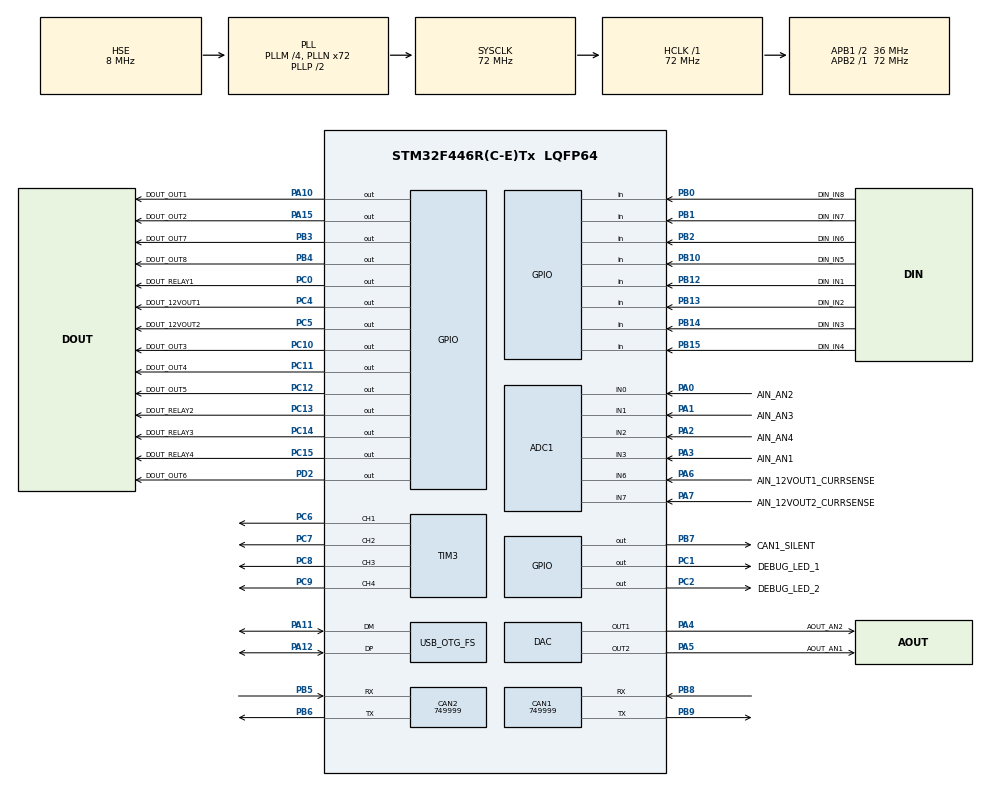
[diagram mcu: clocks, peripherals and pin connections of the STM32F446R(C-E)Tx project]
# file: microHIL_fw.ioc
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ADC1.Channel-0\#ChannelRegularConversion=ADC_CHANNEL_0
ADC1.NbrOfConversionFlag=1
ADC1.Rank-0\#ChannelRegularConversion=1
ADC1.SamplingTime-0\#ChannelRegularConversion=ADC_SAMPLETIME_3CYCLES
ADC1.master=1
CAN1.BS1=CAN_BS1_1TQ
CAN1.BS2=CAN_BS2_1TQ
CAN1.CalculateBaudRate=749999
CAN1.CalculateTimeBit=1333
CAN1.CalculateTimeQuantum=444.44444444444446
CAN2.BS1=CAN_BS1_1TQ
CAN2.BS2=CAN_BS2_1TQ
CAN2.CalculateBaudRate=749999
CAN2.CalculateTimeBit=1333
CAN2.CalculateTimeQuantum=444.44444444444446
Mcu.Family=STM32F4
Mcu.Name=STM32F446R(C-E)Tx
Mcu.Package=LQFP64
NVIC.OTG_FS_IRQn=true\:0\:0\:false\:false\:true\:false\:true\:true
NVIC.PriorityGroup=NVIC_PRIORITYGROUP_4
PA0-WKUP.GPIO_Label=AIN_AN2
PA0-WKUP.Signal=ADCx_IN0
PA1.GPIO_Label=AIN_AN3
PA1.Signal=ADCx_IN1
PA10.GPIO_Label=DOUT_OUT1
PA10.Signal=GPIO_Output
PA11.Mode=Device_Only
PA11.Signal=USB_OTG_FS_DM
PA12.Mode=Device_Only
PA12.Signal=USB_OTG_FS_DP
PA13.Mode=Serial_Wire
PA13.Signal=SYS_JTMS-SWDIO
PA14.Mode=Serial_Wire
PA14.Signal=SYS_JTCK-SWCLK
PA15.GPIO_Label=DOUT_OUT2
PA15.Signal=GPIO_Output
PA2.GPIO_Label=AIN_AN4
PA2.Signal=ADCx_IN2
PA3.GPIO_Label=AIN_AN1
PA3.Signal=ADCx_IN3
PA4.GPIO_Label=AOUT_AN2
PA4.Signal=COMP_DAC1_group
PA5.GPIO_Label=AOUT_AN1
PA5.Signal=COMP_DAC2_group
PA6.GPIO_Label=AIN_12VOUT1_CURRSENSE
PA6.Signal=ADCx_IN6
PA7.GPIO_Label=AIN_12VOUT2_CURRSENSE
PA7.Signal=ADCx_IN7
PB0.GPIO_Label=DIN_IN8
PB0.Signal=GPIO_Input
PB1.GPIO_Label=DIN_IN7
PB1.Signal=GPIO_Input
PB10.GPIO_Label=DIN_IN5
PB10.Signal=GPIO_Input
PB12.GPIO_Label=DIN_IN1
PB12.Signal=GPIO_Input
PB13.GPIO_Label=DIN_IN2
PB13.Signal=GPIO_Input
PB14.GPIO_Label=DIN_IN3
PB14.Signal=GPIO_Input
PB15.GPIO_Label=DIN_IN4
PB15.Signal=GPIO_Input
PB2.GPIO_Label=DIN_IN6
PB2.Signal=GPIO_Input
PB3.GPIO_Label=DOUT_OUT7
PB3.Signal=GPIO_Output
PB4.GPIO_Label=DOUT_OUT8
PB4.Signal=GPIO_Output
PB5.Mode=CAN_Activate
PB5.Signal=CAN2_RX
PB6.Mode=CAN_Activate
PB6.Signal=CAN2_TX
PB7.GPIO_Label=CAN1_SILENT
PB7.Signal=GPIO_Output
PB8.Mode=CAN_Activate
PB8.Signal=CAN1_RX
PB9.Mode=CAN_Activate
PB9.Signal=CAN1_TX
PC0.GPIO_Label=DOUT_RELAY1
PC0.Signal=GPIO_Output
PC1.GPIO_Label=DEBUG_LED_1
PC1.Signal=GPIO_Output
PC10.GPIO_Label=DOUT_OUT3
PC10.Signal=GPIO_Output
PC11.GPIO_Label=DOUT_OUT4
PC11.Signal=GPIO_Output
PC12.GPIO_Label=DOUT_OUT5
PC12.Signal=GPIO_Output
PC13.GPIO_Label=DOUT_RELAY2
PC13.Signal=GPIO_Output
PC14-OSC32_IN.GPIO_Label=DOUT_RELAY3
PC14-OSC32_IN.Signal=GPIO_Output
PC15-OSC32_OUT.GPIO_Label=DOUT_RELAY4
PC15-OSC32_OUT.Signal=GPIO_Output
PC2.GPIO_Label=DEBUG_LED_2
PC2.Signal=GPIO_Output
PC4.GPIO_Label=DOUT_12VOUT1
PC4.Signal=GPIO_Output
PC5.GPIO_Label=DOUT_12VOUT2
PC5.Signal=GPIO_Output
PC6.Signal=S_TIM3_CH1
PC7.Signal=S_TIM3_CH2
PC8.Signal=S_TIM3_CH3
PC9.Signal=S_TIM3_CH4
PD2.GPIO_Label=DOUT_OUT6
PD2.Signal=GPIO_Output
PH0-OSC_IN.Mode=HSE-External-Oscillator
PH0-OSC_IN.Signal=RCC_OSC_IN
PH1-OSC_OUT.Mode=HSE-External-Oscillator
PH1-OSC_OUT.Signal=RCC_OSC_OUT
ProjectManager.HeapSize=0x200
ProjectManager.StackSize=0x400
ProjectManager.TargetToolchain=CMake
RCC.AHBFreq_Value=72000000
RCC.APB1CLKDivider=RCC_HCLK_DIV2
RCC.APB1Freq_Value=36000000
RCC.APB1TimFreq_Value=72000000
RCC.APB2Freq_Value=72000000
RCC.APB2TimFreq_Value=72000000
RCC.CortexFreq_Value=72000000
RCC.HCLKFreq_Value=72000000
RCC.HSE_VALUE=8000000
RCC.PLLM=4
RCC.PLLN=72
RCC.PLLQ=3
RCC.SYSCLKFreq_VALUE=72000000
RCC.SYSCLKSource=RCC_SYSCLKSOURCE_PLLCLK
RCC.USBFreq_Value=48000000
RCC.VCOOutputFreq_Value=144000000
SH.ADCx_IN0.0=ADC1_IN0,IN0
SH.ADCx_IN1.0=ADC1_IN1,IN1
SH.ADCx_IN2.0=ADC1_IN2,IN2
SH.ADCx_IN3.0=ADC1_IN3,IN3
SH.ADCx_IN6.0=ADC1_IN6,IN6
SH.ADCx_IN7.0=ADC1_IN7,IN7
SH.COMP_DAC1_group.0=DAC_OUT1,DAC_OUT1
SH.COMP_DAC2_group.0=DAC_OUT2,DAC_OUT2
SH.S_TIM3_CH1.0=TIM3_CH1,PWM Generation1 CH1
SH.S_TIM3_CH2.0=TIM3_CH2,PWM Generation2 CH2
SH.S_TIM3_CH3.0=TIM3_CH3,PWM Generation3 CH3
SH.S_TIM3_CH4.0=TIM3_CH4,PWM Generation4 CH4
TIM3.Channel-PWM\ Generation1\ CH1=TIM_CHANNEL_1
TIM3.Channel-PWM\ Generation2\ CH2=TIM_CHANNEL_2
TIM3.Channel-PWM\ Generation3\ CH3=TIM_CHANNEL_3
TIM3.Channel-PWM\ Generation4\ CH4=TIM_CHANNEL_4
USB_DEVICE.CLASS_NAME_FS=CDC
USB_DEVICE.VirtualMode-CDC_FS=Cdc
USB_DEVICE.VirtualModeFS=Cdc_FS
USB_OTG_FS.VirtualMode=Device_Only
VP_USB_DEVICE_VS_USB_DEVICE_CDC_FS.Mode=CDC_FS
board=custom

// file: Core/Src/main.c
/* USER CODE BEGIN Header */
/**
  ******************************************************************************
  * @file           : main.c
  * @brief          : Main program body
  ******************************************************************************
  * @attention
  *
  * Copyright (c) 2026 STMicroelectronics.
  * All rights reserved.
  *
  * This software is licensed under terms that can be found in the LICENSE file
  * in the root directory of this software component.
  * If no LICENSE file comes with this software, it is provided AS-IS.
  *
  ******************************************************************************
  */
/* USER CODE END Header */
#include "main.h"
#include "usb_device.h"

/* USER CODE BEGIN Includes */
#include "protocol.h"
#include "slcan.h"
/* USER CODE END Includes */

ADC_HandleTypeDef hadc1;

CAN_HandleTypeDef hcan1;
CAN_HandleTypeDef hcan2;

DAC_HandleTypeDef hdac;

TIM_HandleTypeDef htim3;

void SystemClock_Config(void);
static void MX_GPIO_Init(void);
static void MX_ADC1_Init(void);
static void MX_CAN1_Init(void);
static void MX_CAN2_Init(void);
static void MX_DAC_Init(void);
static void MX_TIM3_Init(void);

int main(void)
{

  /* MCU Configuration--------------------------------------------------------*/

  /* Reset of all peripherals, Initializes the Flash interface and the Systick. */
  HAL_Init();

  /* Configure the system clock */
  SystemClock_Config();

  /* Initialize all configured peripherals */
  MX_GPIO_Init();
  MX_USB_DEVICE_Init();
  MX_ADC1_Init();
  MX_CAN1_Init();
  MX_CAN2_Init();
  MX_DAC_Init();
  MX_TIM3_Init();

  /* Infinite loop */
  while (1)
  {

    /* USER CODE BEGIN 3 */
    Protocol_Poll();
    Slcan_Poll();
  }
  /* USER CODE END 3 */
}

void SystemClock_Config(void)
{
  RCC_OscInitTypeDef RCC_OscInitStruct = {0};
  RCC_ClkInitTypeDef RCC_ClkInitStruct = {0};

  /** Configure the main internal regulator output voltage
  */
  __HAL_RCC_PWR_CLK_ENABLE();
  __HAL_PWR_VOLTAGESCALING_CONFIG(PWR_REGULATOR_VOLTAGE_SCALE3);

  /** Initializes the RCC Oscillators according to the specified parameters
  * in the RCC_OscInitTypeDef structure.
  */
  RCC_OscInitStruct.OscillatorType = RCC_OSCILLATORTYPE_HSE;
  RCC_OscInitStruct.HSEState = RCC_HSE_ON;
  RCC_OscInitStruct.PLL.PLLState = RCC_PLL_ON;
  RCC_OscInitStruct.PLL.PLLSource = RCC_PLLSOURCE_HSE;
  RCC_OscInitStruct.PLL.PLLM = 4;
  RCC_OscInitStruct.PLL.PLLN = 72;
  RCC_OscInitStruct.PLL.PLLP = RCC_PLLP_DIV2;
  RCC_OscInitStruct.PLL.PLLQ = 3;
  RCC_OscInitStruct.PLL.PLLR = 2;
  if (HAL_RCC_OscConfig(&RCC_OscInitStruct) != HAL_OK)
  {
    Error_Handler();
  }

  /** Initializes the CPU, AHB and APB buses clocks
  */
  RCC_ClkInitStruct.ClockType = RCC_CLOCKTYPE_HCLK|RCC_CLOCKTYPE_SYSCLK
                              |RCC_CLOCKTYPE_PCLK1|RCC_CLOCKTYPE_PCLK2;
  RCC_ClkInitStruct.SYSCLKSource = RCC_SYSCLKSOURCE_PLLCLK;
  RCC_ClkInitStruct.AHBCLKDivider = RCC_SYSCLK_DIV1;
  RCC_ClkInitStruct.APB1CLKDivider = RCC_HCLK_DIV2;
  RCC_ClkInitStruct.APB2CLKDivider = RCC_HCLK_DIV1;

  if (HAL_RCC_ClockConfig(&RCC_ClkInitStruct, FLASH_LATENCY_2) != HAL_OK)
  {
    Error_Handler();
  }
}

static void MX_ADC1_Init(void)
{

  ADC_ChannelConfTypeDef sConfig = {0};

  /** Configure the global features of the ADC (Clock, Resolution, Data Alignment and number of conversion)
  */
  hadc1.Instance = ADC1;
  hadc1.Init.ClockPrescaler = ADC_CLOCK_SYNC_PCLK_DIV2;
  hadc1.Init.Resolution = ADC_RESOLUTION_12B;
  hadc1.Init.ScanConvMode = DISABLE;
  hadc1.Init.ContinuousConvMode = DISABLE;
  hadc1.Init.DiscontinuousConvMode = DISABLE;
  hadc1.Init.ExternalTrigConvEdge = ADC_EXTERNALTRIGCONVEDGE_NONE;
  hadc1.Init.ExternalTrigConv = ADC_SOFTWARE_START;
  hadc1.Init.DataAlign = ADC_DATAALIGN_RIGHT;
  hadc1.Init.NbrOfConversion = 1;
  hadc1.Init.DMAContinuousRequests = DISABLE;
  hadc1.Init.EOCSelection = ADC_EOC_SINGLE_CONV;
  if (HAL_ADC_Init(&hadc1) != HAL_OK)
  {
    Error_Handler();
  }

  /** Configure for the selected ADC regular channel its corresponding rank in the sequencer and its sample time.
  */
  sConfig.Channel = ADC_CHANNEL_0;
  sConfig.Rank = 1;
  sConfig.SamplingTime = ADC_SAMPLETIME_3CYCLES;
  if (HAL_ADC_ConfigChannel(&hadc1, &sConfig) != HAL_OK)
  {
    Error_Handler();
  }

}

static void MX_CAN1_Init(void)
{

  hcan1.Instance = CAN1;
  hcan1.Init.Prescaler = 16;
  hcan1.Init.Mode = CAN_MODE_NORMAL;
  hcan1.Init.SyncJumpWidth = CAN_SJW_1TQ;
  hcan1.Init.TimeSeg1 = CAN_BS1_1TQ;
  hcan1.Init.TimeSeg2 = CAN_BS2_1TQ;
  hcan1.Init.TimeTriggeredMode = DISABLE;
  hcan1.Init.AutoBusOff = DISABLE;
  hcan1.Init.AutoWakeUp = DISABLE;
  hcan1.Init.AutoRetransmission = DISABLE;
  hcan1.Init.ReceiveFifoLocked = DISABLE;
  hcan1.Init.TransmitFifoPriority = DISABLE;
  if (HAL_CAN_Init(&hcan1) != HAL_OK)
  {
    Error_Handler();
  }

}

static void MX_CAN2_Init(void)
{

  hcan2.Instance = CAN2;
  hcan2.Init.Prescaler = 16;
  hcan2.Init.Mode = CAN_MODE_NORMAL;
  hcan2.Init.SyncJumpWidth = CAN_SJW_1TQ;
  hcan2.Init.TimeSeg1 = CAN_BS1_1TQ;
  hcan2.Init.TimeSeg2 = CAN_BS2_1TQ;
  hcan2.Init.TimeTriggeredMode = DISABLE;
  hcan2.Init.AutoBusOff = DISABLE;
  hcan2.Init.AutoWakeUp = DISABLE;
  hcan2.Init.AutoRetransmission = DISABLE;
  hcan2.Init.ReceiveFifoLocked = DISABLE;
  hcan2.Init.TransmitFifoPriority = DISABLE;
  if (HAL_CAN_Init(&hcan2) != HAL_OK)
  {
    Error_Handler();
  }

}

static void MX_DAC_Init(void)
{

  DAC_ChannelConfTypeDef sConfig = {0};

  /** DAC Initialization
  */
  hdac.Instance = DAC;
  if (HAL_DAC_Init(&hdac) != HAL_OK)
  {
    Error_Handler();
  }

  /** DAC channel OUT1 config
  */
  sConfig.DAC_Trigger = DAC_TRIGGER_NONE;
  sConfig.DAC_OutputBuffer = DAC_OUTPUTBUFFER_ENABLE;
  if (HAL_DAC_ConfigChannel(&hdac, &sConfig, DAC_CHANNEL_1) != HAL_OK)
  {
    Error_Handler();
  }

  /** DAC channel OUT2 config
  */
  if (HAL_DAC_ConfigChannel(&hdac, &sConfig, DAC_CHANNEL_2) != HAL_OK)
  {
    Error_Handler();
  }

}

static void MX_TIM3_Init(void)
{

  TIM_MasterConfigTypeDef sMasterConfig = {0};
  TIM_OC_InitTypeDef sConfigOC = {0};

  htim3.Instance = TIM3;
  htim3.Init.Prescaler = 0;
  htim3.Init.CounterMode = TIM_COUNTERMODE_UP;
  htim3.Init.Period = 65535;
  htim3.Init.ClockDivision = TIM_CLOCKDIVISION_DIV1;
  htim3.Init.AutoReloadPreload = TIM_AUTORELOAD_PRELOAD_DISABLE;
  if (HAL_TIM_PWM_Init(&htim3) != HAL_OK)
  {
    Error_Handler();
  }
  sMasterConfig.MasterOutputTrigger = TIM_TRGO_RESET;
  sMasterConfig.MasterSlaveMode = TIM_MASTERSLAVEMODE_DISABLE;
  if (HAL_TIMEx_MasterConfigSynchronization(&htim3, &sMasterConfig) != HAL_OK)
  {
    Error_Handler();
  }
  sConfigOC.OCMode = TIM_OCMODE_PWM1;
  sConfigOC.Pulse = 0;
  sConfigOC.OCPolarity = TIM_OCPOLARITY_HIGH;
  sConfigOC.OCFastMode = TIM_OCFAST_DISABLE;
  if (HAL_TIM_PWM_ConfigChannel(&htim3, &sConfigOC, TIM_CHANNEL_1) != HAL_OK)
  {
    Error_Handler();
  }
  if (HAL_TIM_PWM_ConfigChannel(&htim3, &sConfigOC, TIM_CHANNEL_2) != HAL_OK)
  {
    Error_Handler();
  }
  if (HAL_TIM_PWM_ConfigChannel(&htim3, &sConfigOC, TIM_CHANNEL_3) != HAL_OK)
  {
    Error_Handler();
  }
  if (HAL_TIM_PWM_ConfigChannel(&htim3, &sConfigOC, TIM_CHANNEL_4) != HAL_OK)
  {
    Error_Handler();
  }
  HAL_TIM_MspPostInit(&htim3);

}

static void MX_GPIO_Init(void)
{
  GPIO_InitTypeDef GPIO_InitStruct = {0};

  /* GPIO Ports Clock Enable */
  __HAL_RCC_GPIOC_CLK_ENABLE();
  __HAL_RCC_GPIOH_CLK_ENABLE();
  __HAL_RCC_GPIOA_CLK_ENABLE();
  __HAL_RCC_GPIOB_CLK_ENABLE();
  __HAL_RCC_GPIOD_CLK_ENABLE();

  /*Configure GPIO pin Output Level */
  HAL_GPIO_WritePin(GPIOC, DOUT_RELAY2_Pin|DOUT_RELAY3_Pin|DOUT_RELAY4_Pin|DOUT_RELAY1_Pin
                          |DEBUG_LED_1_Pin|DEBUG_LED_2_Pin|DOUT_12VOUT1_Pin|DOUT_12VOUT2_Pin
                          |DOUT_OUT3_Pin|DOUT_OUT4_Pin|DOUT_OUT5_Pin, GPIO_PIN_RESET);

  /*Configure GPIO pin Output Level */
  HAL_GPIO_WritePin(GPIOA, DOUT_OUT1_Pin|DOUT_OUT2_Pin, GPIO_PIN_RESET);

  /*Configure GPIO pin Output Level */
  HAL_GPIO_WritePin(DOUT_OUT6_GPIO_Port, DOUT_OUT6_Pin, GPIO_PIN_RESET);

  /*Configure GPIO pin Output Level */
  HAL_GPIO_WritePin(GPIOB, DOUT_OUT7_Pin|DOUT_OUT8_Pin|CAN1_SILENT_Pin, GPIO_PIN_RESET);

  /*Configure GPIO pins : DOUT_RELAY2_Pin DOUT_RELAY3_Pin DOUT_RELAY4_Pin DOUT_RELAY1_Pin
                           DEBUG_LED_1_Pin DEBUG_LED_2_Pin DOUT_12VOUT1_Pin DOUT_12VOUT2_Pin
                           DOUT_OUT3_Pin DOUT_OUT4_Pin DOUT_OUT5_Pin */
  GPIO_InitStruct.Pin = DOUT_RELAY2_Pin|DOUT_RELAY3_Pin|DOUT_RELAY4_Pin|DOUT_RELAY1_Pin
                          |DEBUG_LED_1_Pin|DEBUG_LED_2_Pin|DOUT_12VOUT1_Pin|DOUT_12VOUT2_Pin
                          |DOUT_OUT3_Pin|DOUT_OUT4_Pin|DOUT_OUT5_Pin;
  GPIO_InitStruct.Mode = GPIO_MODE_OUTPUT_PP;
  GPIO_InitStruct.Pull = GPIO_NOPULL;
  GPIO_InitStruct.Speed = GPIO_SPEED_FREQ_LOW;
  HAL_GPIO_Init(GPIOC, &GPIO_InitStruct);

  /*Configure GPIO pins : DIN_IN8_Pin DIN_IN7_Pin DIN_IN6_Pin DIN_IN5_Pin
                           DIN_IN1_Pin DIN_IN2_Pin DIN_IN3_Pin DIN_IN4_Pin */
  GPIO_InitStruct.Pin = DIN_IN8_Pin|DIN_IN7_Pin|DIN_IN6_Pin|DIN_IN5_Pin
                          |DIN_IN1_Pin|DIN_IN2_Pin|DIN_IN3_Pin|DIN_IN4_Pin;
  GPIO_InitStruct.Mode = GPIO_MODE_INPUT;
  GPIO_InitStruct.Pull = GPIO_NOPULL;
  HAL_GPIO_Init(GPIOB, &GPIO_InitStruct);

  /*Configure GPIO pins : DOUT_OUT1_Pin DOUT_OUT2_Pin */
  GPIO_InitStruct.Pin = DOUT_OUT1_Pin|DOUT_OUT2_Pin;
  GPIO_InitStruct.Mode = GPIO_MODE_OUTPUT_PP;
  GPIO_InitStruct.Pull = GPIO_NOPULL;
  GPIO_InitStruct.Speed = GPIO_SPEED_FREQ_LOW;
  HAL_GPIO_Init(GPIOA, &GPIO_InitStruct);

  /*Configure GPIO pin : DOUT_OUT6_Pin */
  GPIO_InitStruct.Pin = DOUT_OUT6_Pin;
  GPIO_InitStruct.Mode = GPIO_MODE_OUTPUT_PP;
  GPIO_InitStruct.Pull = GPIO_NOPULL;
  GPIO_InitStruct.Speed = GPIO_SPEED_FREQ_LOW;
  HAL_GPIO_Init(DOUT_OUT6_GPIO_Port, &GPIO_InitStruct);

  /*Configure GPIO pins : DOUT_OUT7_Pin DOUT_OUT8_Pin CAN1_SILENT_Pin */
  GPIO_InitStruct.Pin = DOUT_OUT7_Pin|DOUT_OUT8_Pin|CAN1_SILENT_Pin;
  GPIO_InitStruct.Mode = GPIO_MODE_OUTPUT_PP;
  GPIO_InitStruct.Pull = GPIO_NOPULL;
  GPIO_InitStruct.Speed = GPIO_SPEED_FREQ_LOW;
  HAL_GPIO_Init(GPIOB, &GPIO_InitStruct);

}

void Error_Handler(void)
{
  __disable_irq();
  while (1)
  {
  }
}
